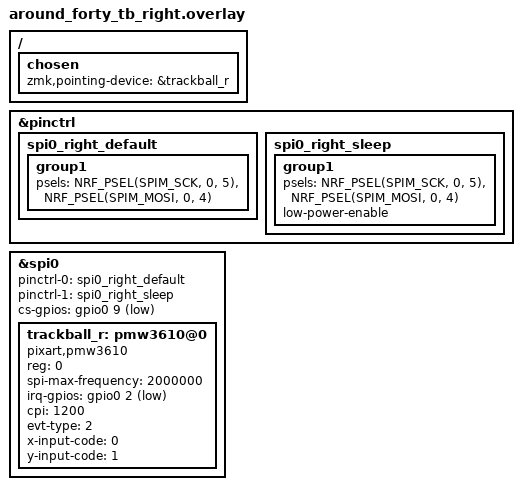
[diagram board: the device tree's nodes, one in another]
/* seeeduino_xiao_ble + PMW3610 (RIGHT / pointer move) */
#include "around_forty_tb.dtsi"   /* ★ dtsi を必ず取り込む */

/* SPI ピン定義（3-wire: SCK=P0.05, SDIO/MOSI=P0.04） */
&pinctrl {
    spi0_right_default: spi0_right_default {
        group1 {
            psels = <NRF_PSEL(SPIM_SCK,  0, 5)>,
                    <NRF_PSEL(SPIM_MOSI, 0, 4)>;
        };
    };
    spi0_right_sleep: spi0_right_sleep {
        group1 {
            psels = <NRF_PSEL(SPIM_SCK,  0, 5)>,
                    <NRF_PSEL(SPIM_MOSI, 0, 4)>;
            low-power-enable;
        };
    };
};

&spi0 {
    status = "okay";
    pinctrl-0 = <&spi0_right_default>;
    pinctrl-1 = <&spi0_right_sleep>;
    pinctrl-names = "default", "sleep";

    /* cs-gpios はバス側に置く */
    cs-gpios = <&gpio0 9 GPIO_ACTIVE_LOW>;  /* ← 実配線に合わせて 9→10 などへ */

    trackball_r: pmw3610@0 {
        compatible = "pixart,pmw3610";
        status = "okay";
        reg = <0>;
        spi-max-frequency = <2000000>;

        /* MOTION 割り込み = P0.02（まずは単一フラグで） */
        irq-gpios = <&gpio0 2 GPIO_ACTIVE_LOW>;

        /* 解像度 */
        cpi = <1200>;

        /* 数値直書き: EV_REL=2, REL_X=0, REL_Y=1 */
        evt-type     = <2>;
        x-input-code = <0>;
        y-input-code = <1>;
    };
};

/* 右手＝ポインティングデバイス */
 /{
    chosen {
        zmk,pointing-device = &trackball_r;
    };
};
